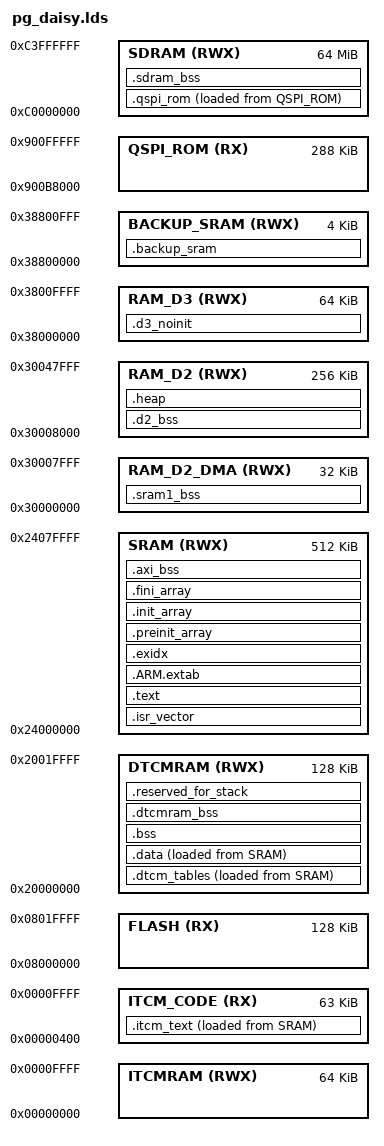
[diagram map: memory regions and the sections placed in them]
/* Pocket Groove on the Daisy Seed (STM32H750IB): RAM-booted (BOOT_SRAM) linker script.
 *
 * Derived from libDaisy's core/STM32H750IB_sram.lds (generated by VisualGDB's
 * LinkerScriptGenerator, BSD licence; libDaisy is MIT). What differs, and why
 * (docs/DAISY.md "Memory map"):
 *   - The image (vectors, code, constants, .data's initial values) is what the Daisy
 *     bootloader copies: exactly 0x78000 bytes (480 KB) from QSPI 0x90040000 to AXI
 *     SRAM 0x24000000 (checked in the bootloader binary). ASSERTed below.
 *   - The big cold constant data (the core's PG_BULK_ATTR, lib/pg/src/pg/table_attr.h:
 *     the sampler's built-in sounds and the built-in instrument library; the Makefile
 *     defines it as this section) does not fit there: it forms .qspi_rom,
 *     loaded right after the image in the same .bin (QSPI 0x900B8000, which the
 *     bootloader leaves alone) and copied to SDRAM by the firmware at boot
 *     (daisy/src/memory.cpp). Nothing runs or reads from QSPI afterwards, so the QSPI
 *     can be erased and written (/int, the sample pool) while the audio plays.
 *   - .bss stays in DTCM (zeroed by the startup code): the engine's state block (the
 *     audio thread's hottest data) and every small variable. .d2_bss (D2 SRAM) and
 *     .axi_bss (AXI SRAM after the image) take the large objects the firmware places
 *     there by name; daisy/src/memory.cpp zeroes them before constructors run.
 *   - SDRAM: .qspi_rom's copy, then .sdram_bss (libDaisy's DSY_SDRAM_BSS: the pool
 *     image, /int's files, buffers). Never zeroed by the startup: SDRAM only works
 *     after DaisySeed::Init.
 *   - BUILD VARIANTS (daisy/Makefile ITCM=1, TABLES=dtcm; docs/DAISY.md section 11): two
 *     fragments the Makefile writes for each build into its own directory (the link's -L),
 *     empty in the default build, so these output sections are empty and vanish:
 *       pg_itcm.ld   the hot audio functions (tools/daisy_itcm.py) -> .itcm_text, run from
 *                    ITCM (zero-wait, no I-cache), loaded from the image by the preinit hook
 *       pg_dtcm.ld   the bass's per-sample tables (sine, BLEP) -> .dtcm_tables in DTCM
 *                    (zero-wait, no D-cache), likewise
 *     Each is placed BEFORE the section whose wildcards would otherwise take its input
 *     sections (the first matching rule wins). Their load addresses are in the image (the
 *     bootloader copies them with the rest), so the image does not shrink.
 */

ENTRY(Reset_Handler)

MEMORY
{
	FLASH       (RX)  : ORIGIN = 0x08000000, LENGTH = 128K   /* the Daisy bootloader */
	DTCMRAM     (RWX) : ORIGIN = 0x20000000, LENGTH = 128K
	SRAM        (RWX) : ORIGIN = 0x24000000, LENGTH = 512K   /* image: first 480K */
	RAM_D2_DMA  (RWX) : ORIGIN = 0x30000000, LENGTH = 32K    /* not cached (libDaisy's MPU) */
	RAM_D2      (RWX) : ORIGIN = 0x30008000, LENGTH = 256K
	RAM_D3      (RWX) : ORIGIN = 0x38000000, LENGTH = 64K
	BACKUP_SRAM (RWX) : ORIGIN = 0x38800000, LENGTH = 4K     /* the bootloader's boot info */
	ITCMRAM     (RWX) : ORIGIN = 0x00000000, LENGTH = 64K
	/* The ITCM's code from 1 KB on: a write through a null pointer (address 0 is ITCM on the
	   H7) then hits nothing that runs. */
	ITCM_CODE   (RX)  : ORIGIN = 0x00000400, LENGTH = 63K
	SDRAM       (RWX) : ORIGIN = 0xc0000000, LENGTH = 64M
	QSPI_ROM    (RX)  : ORIGIN = 0x900B8000, LENGTH = 288K   /* daisy/core/layout.h kRomAddr */
}

_estack = 0x20020000;
_pg_min_stack = 16K;
_pg_image_max = 0x78000;

SECTIONS
{
	.isr_vector :
	{
		. = ALIGN(4);
		_pg_image_start = .;
		KEEP(*(.isr_vector))
		. = ALIGN(4);
	} > SRAM

	/* The hot audio code in ITCM (ITCM=1; empty otherwise), loaded from the image. */
	.itcm_text :
	{
		. = ALIGN(8);
		_sitcm_text = .;
		INCLUDE pg_itcm.ld
		. = ALIGN(8);
		_eitcm_text = .;
	} > ITCM_CODE AT > SRAM
	_siitcm_text = LOADADDR(.itcm_text);

	/* The bass's per-sample tables in DTCM (TABLES=dtcm; empty otherwise), loaded from the image. */
	.dtcm_tables :
	{
		. = ALIGN(8);
		_sdtcm_tables = .;
		INCLUDE pg_dtcm.ld
		. = ALIGN(8);
		_edtcm_tables = .;
	} > DTCMRAM AT > SRAM
	_sidtcm_tables = LOADADDR(.dtcm_tables);

	/* The constant tables that go to QSPI / SDRAM. First, so these input sections are
	   matched here and not by .text's wildcards below. */
	.qspi_rom :
	{
		. = ALIGN(32);
		_sqspi_rom = .;
		KEEP(*(.qspi_rom.marker))
		*(.qspi_rom .qspi_rom.*)
		/* Cold text, by object (docs/DAISY.md "Memory map"): the string literals of
		   the UI (its help text above all), the file formats and the macro text parser,
		   and the demos' strings and note tables. String literals cannot take a section
		   attribute, so they are placed here rather than by a macro in the core. All of
		   it is read only by the main loop after the ROM copy: never before main (no
		   constructor reads it) and never by the audio interrupt. Only strings, plus
		   the demos' tables, which hold no pointers: if the ROM part is missing (zeroed
		   at boot) they read as empty strings and silent notes, never as bad pointers.
		   The Daisy's own report text (daisy/app) stays in the image, so the report
		   still says what is wrong when the ROM part is. (The patterns spell a
		   directory's files as "/?*", since a slash then a star would open a comment.) */
		*/pg/ui/?*.o(.rodata*.str1.*)
		*/pg/io/?*.o(.rodata*.str1.*)
		*/pg/macro/macro_parse.o(.rodata*.str1.*)
		*/pg/demo/?*.o(.rodata*.str1.*)
		*/pg/demo/demo_*.o(.rodata .rodata.*)
		/* The bench's text (daisy/app/app_bench.cpp: the >bench table, the late-block
		   records): main loop only, long after the ROM copy. */
		*/daisy/app/app_bench.o(.rodata*.str1.*)
		. = ALIGN(32);
		_eqspi_rom = .;
	} > SDRAM AT > QSPI_ROM
	_siqspi_rom = LOADADDR(.qspi_rom);

	.text :
	{
		. = ALIGN(4);
		_stext = .;
		*(.text)
		*(.text*)
		*(.rodata)
		*(.rodata*)
		*(.glue_7)
		*(.glue_7t)
		KEEP(*(.init))
		KEEP(*(.fini))
		. = ALIGN(4);
		_etext = .;
	} > SRAM

	.ARM.extab :
	{
		. = ALIGN(4);
		*(.ARM.extab)
		*(.gnu.linkonce.armextab.*)
		. = ALIGN(4);
	} > SRAM

	.exidx :
	{
		. = ALIGN(4);
		PROVIDE(__exidx_start = .);
		*(.ARM.exidx*)
		. = ALIGN(4);
		PROVIDE(__exidx_end = .);
	} > SRAM

	.ARM.attributes 0 : { *(.ARM.attributes) }

	.preinit_array :
	{
		PROVIDE_HIDDEN(__preinit_array_start = .);
		KEEP(*(.preinit_array*))
		PROVIDE_HIDDEN(__preinit_array_end = .);
	} > SRAM

	.init_array :
	{
		PROVIDE_HIDDEN(__init_array_start = .);
		KEEP(*(SORT(.init_array.*)))
		KEEP(*(.init_array*))
		PROVIDE_HIDDEN(__init_array_end = .);
	} > SRAM

	.fini_array :
	{
		PROVIDE_HIDDEN(__fini_array_start = .);
		KEEP(*(.fini_array*))
		KEEP(*(SORT(.fini_array.*)))
		PROVIDE_HIDDEN(__fini_array_end = .);
	} > SRAM

	.sram1_bss (NOLOAD) :
	{
		. = ALIGN(4);
		_ssram1_bss = .;
		PROVIDE(__sram1_bss_start__ = _sram1_bss);
		*(.sram1_bss)
		*(.sram1_bss*)
		. = ALIGN(4);
		_esram1_bss = .;
		PROVIDE(__sram1_bss_end__ = _esram1_bss);
	} > RAM_D2_DMA

	.data :
	{
		. = ALIGN(4);
		_sdata = .;
		PROVIDE(__data_start__ = _sdata);
		*(.data)
		*(.data*)
		. = ALIGN(4);
		_edata = .;
		PROVIDE(__data_end__ = _edata);
	} > DTCMRAM AT > SRAM

	_sidata = LOADADDR(.data);
	_pg_image_end = LOADADDR(.data) + SIZEOF(.data);

	.bss (NOLOAD) :
	{
		. = ALIGN(4);
		_sbss = .;
		PROVIDE(__bss_start__ = _sbss);
		/* The engine's state block first, bracketed so the bench can say where it is. */
		_pg_engine_state = .;
		*/pg/engine/engine.o(.bss .bss.*)
		_pg_engine_state_end = .;
		*(.bss)
		*(.bss*)
		*(COMMON)
		. = ALIGN(4);
		_ebss = .;
		PROVIDE(__bss_end__ = _ebss);
	} > DTCMRAM

	.dtcmram_bss (NOLOAD) :
	{
		. = ALIGN(4);
		_sdtcmram_bss = .;
		PROVIDE(__dtcmram_bss_start__ = _sdtcmram_bss);
		*(.dtcmram_bss)
		*(.dtcmram_bss*)
		. = ALIGN(4);
		_edtcmram_bss = .;
		PROVIDE(__dtcmram_bss_end__ = _edtcmram_bss);
	} > DTCMRAM

	/* AXI SRAM after the image, including the 32 KB the bootloader used while it ran. */
	.axi_bss (NOLOAD) :
	{
		. = ALIGN(32);
		_saxi_bss = .;
		*(.axi_bss)
		*(.axi_bss*)
		. = ALIGN(32);
		_eaxi_bss = .;
	} > SRAM

	.d2_bss (NOLOAD) :
	{
		. = ALIGN(32);
		_sd2_bss = .;
		*(.d2_bss)
		*(.d2_bss*)
		. = ALIGN(32);
		_ed2_bss = .;
	} > RAM_D2

	.sdram_bss (NOLOAD) :
	{
		. = ALIGN(32);
		_ssdram_bss = .;
		PROVIDE(__sdram_bss_start = _ssdram_bss);
		*(.sdram_bss)
		*(.sdram_bss*)
		. = ALIGN(32);
		_esdram_bss = .;
		PROVIDE(__sdram_bss_end = _esdram_bss);
	} > SDRAM

	/* Kept over a reset (nobody clears it): the fault record (daisy/src/memory.cpp). */
	.d3_noinit (NOLOAD) :
	{
		. = ALIGN(4);
		_sd3_noinit = .;
		*(.d3_noinit)
		*(.d3_noinit*)
		. = ALIGN(4);
		_ed3_noinit = .;
	} > RAM_D3

	.backup_sram (NOLOAD) :
	{
		. = ALIGN(4);
		_sbackup_sram = .;
		PROVIDE(__backup_sram_start = _sbackup_sram);
		*(.backup_sram)
		*(.backup_sram*)
		. = ALIGN(4);
		_ebackup_sram = .;
		PROVIDE(__backup_sram_end = _ebackup_sram);
	} > BACKUP_SRAM

	/* newlib's heap (nothing of ours allocates; libc might, once): D2 after .d2_bss. */
	.heap (NOLOAD) :
	{
		. = ALIGN(8);
		PROVIDE(__heap_start__ = .);
		PROVIDE(__heap_start = .);
		KEEP(*(.heap))
		. = ALIGN(8);
		PROVIDE(__heap_end = .);
		PROVIDE(__heap_end__ = .);
	} > RAM_D2

	PROVIDE(end = .);
	_pg_d2_end = .;

	.reserved_for_stack (NOLOAD) :
	{
		. = ALIGN(4);
		PROVIDE(__reserved_for_stack_start__ = .);
		KEEP(*(.reserved_for_stack))
		. = ALIGN(4);
		PROVIDE(__reserved_for_stack_end__ = .);
	} > DTCMRAM

}

ASSERT(_pg_image_end - _pg_image_start <= _pg_image_max,
       "the RAM image is larger than the 480 KB the Daisy bootloader copies: move more to .qspi_rom")
ASSERT(_estack - _edtcmram_bss >= _pg_min_stack, "less than 16 KB of DTCM left for the stack")
ASSERT(_eqspi_rom - _sqspi_rom <= LENGTH(QSPI_ROM), "the ROM part does not fit its QSPI region")
